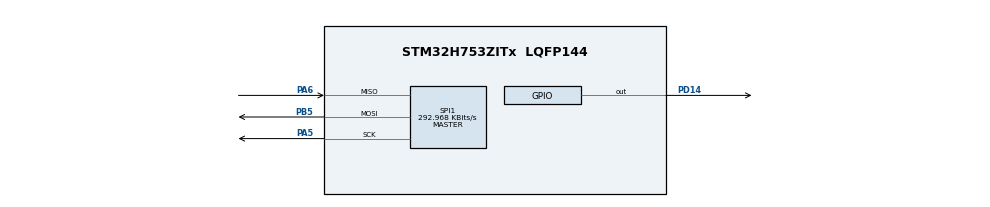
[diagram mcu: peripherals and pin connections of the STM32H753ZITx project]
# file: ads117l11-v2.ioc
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CORTEX_M7.CPU_DCache=Disabled
CORTEX_M7.CPU_ICache=Disabled
CORTEX_M7.MPU_Control=__NULL
CORTEX_M7.default_mode_Activation=1
Mcu.Family=STM32H7
Mcu.Name=STM32H753ZITx
Mcu.Package=LQFP144
NUCLEO-H753ZI.BUTTON=1
NUCLEO-H753ZI.LD1=true
NUCLEO-H753ZI.LD2=true
NUCLEO-H753ZI.LD3=true
NUCLEO-H753ZI.VCP=true
NVIC.EXTI15_10_IRQn=true\:0\:0\:false\:false\:true\:false\:true\:true
NVIC.PriorityGroup=NVIC_PRIORITYGROUP_4
PA5.GPIO_Speed=GPIO_SPEED_FREQ_VERY_HIGH
PA5.Mode=Full_Duplex_Master
PA5.Signal=SPI1_SCK
PA6.GPIO_Speed=GPIO_SPEED_FREQ_VERY_HIGH
PA6.Mode=Full_Duplex_Master
PA6.Signal=SPI1_MISO
PB5.GPIO_Speed=GPIO_SPEED_FREQ_VERY_HIGH
PB5.Mode=Full_Duplex_Master
PB5.Signal=SPI1_MOSI
PC14-OSC32_IN\ (OSC32_IN).Signal=RCC_OSC32_IN
PC15-OSC32_OUT\ (OSC32_OUT).Signal=RCC_OSC32_OUT
PD14.GPIO_Speed=GPIO_SPEED_FREQ_VERY_HIGH
PD14.PinState=GPIO_PIN_SET
PD14.Signal=GPIO_Output
PD8.Signal=USART3_TX
PD9.Signal=USART3_RX
PH0-OSC_IN\ (PH0).Signal=RCC_OSC_IN
PH1-OSC_OUT\ (PH1).Signal=RCC_OSC_OUT
ProjectManager.HeapSize=0x200
ProjectManager.StackSize=0x400
ProjectManager.TargetToolchain=CMake
RCC.ADCFreq_Value=129000000
RCC.APB1Freq_Value=16000000
RCC.APB2Freq_Value=16000000
RCC.APB3Freq_Value=16000000
RCC.APB4Freq_Value=16000000
RCC.CortexFreq_Value=64000000
RCC.D1PPRE=RCC_APB3_DIV2
RCC.D2PPRE1=RCC_APB1_DIV2
RCC.D2PPRE2=RCC_APB2_DIV2
RCC.D3PPRE=RCC_APB4_DIV2
RCC.DIVM1=4
RCC.DIVN1=9
RCC.HCLKFreq_Value=32000000
RCC.HPRE=RCC_HCLK_DIV2
RCC.HSE_VALUE=8000000
RCC.PLLFRACN=3072
RCC.SYSCLKFreq_VALUE=64000000
RCC.USBFreq_Value=75000000
SPI1.BaudRatePrescaler=SPI_BAUDRATEPRESCALER_256
SPI1.CLKPhase=SPI_PHASE_2EDGE
SPI1.CalculateBaudRate=292.968 KBits/s
SPI1.DataSize=SPI_DATASIZE_8BIT
SPI1.Direction=SPI_DIRECTION_2LINES
SPI1.Mode=SPI_MODE_MASTER
SPI1.VirtualType=VM_MASTER
VP_MEMORYMAP_VS_MEMORYMAP.Mode=CurAppReg
VP_NUCLEO-H753ZI_VS_BSP_COMMON.Mode=COMMON
board=NUCLEO-H753ZI

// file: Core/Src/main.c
/* USER CODE BEGIN Header */
/**
 ******************************************************************************
 * @file           : main.c
 * @brief          : Main program body
 ******************************************************************************
 * @attention
 *
 * Copyright (c) 2026 STMicroelectronics.
 * All rights reserved.
 *
 * This software is licensed under terms that can be found in the LICENSE file
 * in the root directory of this software component.
 * If no LICENSE file comes with this software, it is provided AS-IS.
 *
 ******************************************************************************
 */
/* USER CODE END Header */
#include "main.h"
#include "cpp_main.hpp"

COM_InitTypeDef BspCOMInit;

SPI_HandleTypeDef hspi1;

void SystemClock_Config(void);
static void MX_GPIO_Init(void);
static void MX_SPI1_Init(void);

int main(void) {

	/* MCU
	 * Configuration--------------------------------------------------------*/

	/* Reset of all peripherals, Initializes the Flash interface and the
	 * Systick. */
	HAL_Init();

	/* Configure the system clock */
	SystemClock_Config();

	/* Initialize all configured peripherals */
	MX_GPIO_Init();
	MX_SPI1_Init();

	/* Initialize leds */
	BSP_LED_Init(LED_GREEN);
	BSP_LED_Init(LED_YELLOW);
	BSP_LED_Init(LED_RED);

	/* Initialize USER push-button, will be used to trigger an interrupt each
	 * time it's pressed.*/
	BSP_PB_Init(BUTTON_USER, BUTTON_MODE_EXTI);

	/* Initialize COM1 port (115200, 8 bits (7-bit data + 1 stop bit), no parity
	 */
	BspCOMInit.BaudRate = 115200;
	BspCOMInit.WordLength = COM_WORDLENGTH_8B;
	BspCOMInit.StopBits = COM_STOPBITS_1;
	BspCOMInit.Parity = COM_PARITY_NONE;
	BspCOMInit.HwFlowCtl = COM_HWCONTROL_NONE;
	if (BSP_COM_Init(COM1, &BspCOMInit) != BSP_ERROR_NONE) {
		Error_Handler();
	}

	/* Infinite loop */
	/* USER CODE BEGIN WHILE */
	application_entry();

	while (1) {
		// HAL_GPIO_WritePin(GPIOD, GPIO_PIN_14, GPIO_PIN_RESET);
		// HAL_SPI_TransmitReceive(&hspi1, txBuffer, rxBuffer, sizeof(txBuffer),
		// 						HAL_MAX_DELAY);
		// HAL_GPIO_WritePin(GPIOD, GPIO_PIN_14, GPIO_PIN_SET);
		/* USER CODE END WHILE */

	}
}

void SystemClock_Config(void) {
	RCC_OscInitTypeDef RCC_OscInitStruct = {0};
	RCC_ClkInitTypeDef RCC_ClkInitStruct = {0};

	/** Supply configuration update enable
	 */
	HAL_PWREx_ConfigSupply(PWR_LDO_SUPPLY);

	/** Configure the main internal regulator output voltage
	 */
	__HAL_PWR_VOLTAGESCALING_CONFIG(PWR_REGULATOR_VOLTAGE_SCALE3);

	while (!__HAL_PWR_GET_FLAG(PWR_FLAG_VOSRDY)) {
	}

	/** Initializes the RCC Oscillators according to the specified parameters
	 * in the RCC_OscInitTypeDef structure.
	 */
	RCC_OscInitStruct.OscillatorType = RCC_OSCILLATORTYPE_HSI;
	RCC_OscInitStruct.HSIState = RCC_HSI_DIV1;
	RCC_OscInitStruct.HSICalibrationValue = RCC_HSICALIBRATION_DEFAULT;
	RCC_OscInitStruct.PLL.PLLState = RCC_PLL_ON;
	RCC_OscInitStruct.PLL.PLLSource = RCC_PLLSOURCE_HSI;
	RCC_OscInitStruct.PLL.PLLM = 4;
	RCC_OscInitStruct.PLL.PLLN = 9;
	RCC_OscInitStruct.PLL.PLLP = 2;
	RCC_OscInitStruct.PLL.PLLQ = 2;
	RCC_OscInitStruct.PLL.PLLR = 2;
	RCC_OscInitStruct.PLL.PLLRGE = RCC_PLL1VCIRANGE_3;
	RCC_OscInitStruct.PLL.PLLVCOSEL = RCC_PLL1VCOMEDIUM;
	RCC_OscInitStruct.PLL.PLLFRACN = 3072;
	if (HAL_RCC_OscConfig(&RCC_OscInitStruct) != HAL_OK) {
		Error_Handler();
	}

	/** Initializes the CPU, AHB and APB buses clocks
	 */
	RCC_ClkInitStruct.ClockType = RCC_CLOCKTYPE_HCLK | RCC_CLOCKTYPE_SYSCLK |
								  RCC_CLOCKTYPE_PCLK1 | RCC_CLOCKTYPE_PCLK2 |
								  RCC_CLOCKTYPE_D3PCLK1 | RCC_CLOCKTYPE_D1PCLK1;
	RCC_ClkInitStruct.SYSCLKSource = RCC_SYSCLKSOURCE_HSI;
	RCC_ClkInitStruct.SYSCLKDivider = RCC_SYSCLK_DIV1;
	RCC_ClkInitStruct.AHBCLKDivider = RCC_HCLK_DIV2;
	RCC_ClkInitStruct.APB3CLKDivider = RCC_APB3_DIV2;
	RCC_ClkInitStruct.APB1CLKDivider = RCC_APB1_DIV2;
	RCC_ClkInitStruct.APB2CLKDivider = RCC_APB2_DIV2;
	RCC_ClkInitStruct.APB4CLKDivider = RCC_APB4_DIV2;

	if (HAL_RCC_ClockConfig(&RCC_ClkInitStruct, FLASH_LATENCY_0) != HAL_OK) {
		Error_Handler();
	}
}

static void MX_SPI1_Init(void) {

	/* SPI1 parameter configuration*/
	hspi1.Instance = SPI1;
	hspi1.Init.Mode = SPI_MODE_MASTER;
	hspi1.Init.Direction = SPI_DIRECTION_2LINES;
	hspi1.Init.DataSize = SPI_DATASIZE_8BIT;
	hspi1.Init.CLKPolarity = SPI_POLARITY_LOW;
	hspi1.Init.CLKPhase = SPI_PHASE_2EDGE;
	hspi1.Init.NSS = SPI_NSS_SOFT;
	hspi1.Init.BaudRatePrescaler = SPI_BAUDRATEPRESCALER_256;
	hspi1.Init.FirstBit = SPI_FIRSTBIT_MSB;
	hspi1.Init.TIMode = SPI_TIMODE_DISABLE;
	hspi1.Init.CRCCalculation = SPI_CRCCALCULATION_DISABLE;
	hspi1.Init.CRCPolynomial = 0x0;
	hspi1.Init.NSSPMode = SPI_NSS_PULSE_ENABLE;
	hspi1.Init.NSSPolarity = SPI_NSS_POLARITY_LOW;
	hspi1.Init.FifoThreshold = SPI_FIFO_THRESHOLD_01DATA;
	hspi1.Init.TxCRCInitializationPattern =
		SPI_CRC_INITIALIZATION_ALL_ZERO_PATTERN;
	hspi1.Init.RxCRCInitializationPattern =
		SPI_CRC_INITIALIZATION_ALL_ZERO_PATTERN;
	hspi1.Init.MasterSSIdleness = SPI_MASTER_SS_IDLENESS_00CYCLE;
	hspi1.Init.MasterInterDataIdleness = SPI_MASTER_INTERDATA_IDLENESS_00CYCLE;
	hspi1.Init.MasterReceiverAutoSusp = SPI_MASTER_RX_AUTOSUSP_DISABLE;
	hspi1.Init.MasterKeepIOState = SPI_MASTER_KEEP_IO_STATE_DISABLE;
	hspi1.Init.IOSwap = SPI_IO_SWAP_DISABLE;
	if (HAL_SPI_Init(&hspi1) != HAL_OK) {
		Error_Handler();
	}
}

static void MX_GPIO_Init(void) {
	GPIO_InitTypeDef GPIO_InitStruct = {0};

	/* GPIO Ports Clock Enable */
	__HAL_RCC_GPIOC_CLK_ENABLE();
	__HAL_RCC_GPIOH_CLK_ENABLE();
	__HAL_RCC_GPIOA_CLK_ENABLE();
	__HAL_RCC_GPIOD_CLK_ENABLE();
	__HAL_RCC_GPIOB_CLK_ENABLE();

	/*Configure GPIO pin Output Level */
	HAL_GPIO_WritePin(GPIOD, GPIO_PIN_14, GPIO_PIN_SET);

	/*Configure GPIO pin : PD14 */
	GPIO_InitStruct.Pin = GPIO_PIN_14;
	GPIO_InitStruct.Mode = GPIO_MODE_OUTPUT_PP;
	GPIO_InitStruct.Pull = GPIO_NOPULL;
	GPIO_InitStruct.Speed = GPIO_SPEED_FREQ_VERY_HIGH;
	HAL_GPIO_Init(GPIOD, &GPIO_InitStruct);

}

void Error_Handler(void) {
	/* USER CODE BEGIN Error_Handler_Debug */
	/* User can add his own implementation to report the HAL error return state
	 */
	__disable_irq();
	while (1) {
	}
	/* USER CODE END Error_Handler_Debug */
}
#ifdef USE_FULL_ASSERT
/**
 * @brief  Reports the name of the source file and the source line number
 *         where the assert_param error has occurred.
 * @param  file: pointer to the source file name
 * @param  line: assert_param error line source number
 * @retval None
 */
void assert_failed(uint8_t *file, uint32_t line) {
	/* USER CODE BEGIN 6 */
	/* User can add his own implementation to report the file name and line
	   number, ex: printf("Wrong parameters value: file %s on line %d\r\n",
	   file, line) */
	/* USER CODE END 6 */
}
#endif /* USE_FULL_ASSERT */
